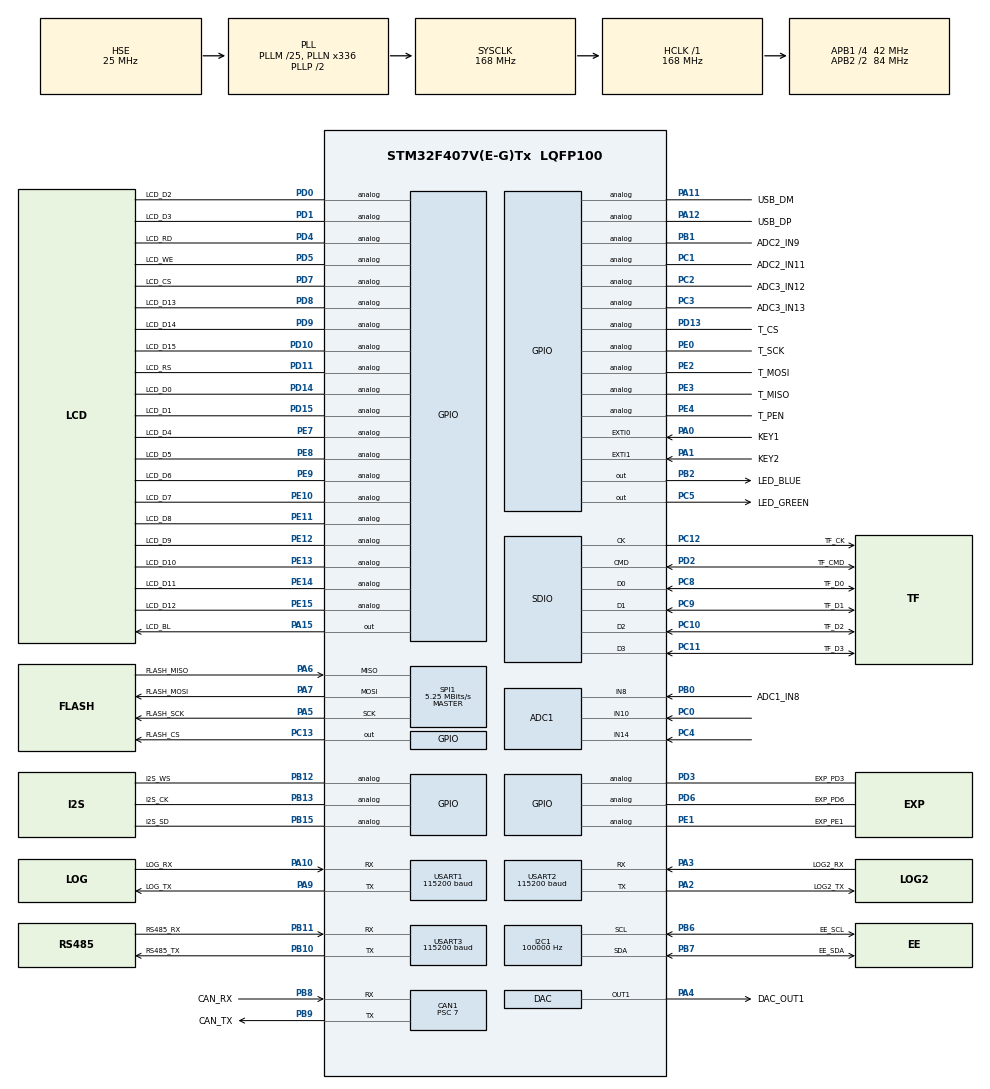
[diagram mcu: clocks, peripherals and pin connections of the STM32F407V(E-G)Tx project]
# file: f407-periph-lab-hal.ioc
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ADC1.Channel-0\#ChannelRegularConversion=ADC_CHANNEL_8
ADC1.Channel-1\#ChannelRegularConversion=ADC_CHANNEL_10
ADC1.Channel-2\#ChannelRegularConversion=ADC_CHANNEL_14
ADC1.Channel-3\#ChannelRegularConversion=ADC_CHANNEL_VREFINT
ADC1.NbrOfConversion=4
ADC1.NbrOfConversionFlag=1
ADC1.Rank-0\#ChannelRegularConversion=1
ADC1.Rank-1\#ChannelRegularConversion=2
ADC1.Rank-2\#ChannelRegularConversion=3
ADC1.Rank-3\#ChannelRegularConversion=4
ADC1.SamplingTime-0\#ChannelRegularConversion=ADC_SAMPLETIME_3CYCLES
ADC1.SamplingTime-1\#ChannelRegularConversion=ADC_SAMPLETIME_3CYCLES
ADC1.SamplingTime-2\#ChannelRegularConversion=ADC_SAMPLETIME_3CYCLES
ADC1.SamplingTime-3\#ChannelRegularConversion=ADC_SAMPLETIME_480CYCLES
ADC1.master=1
CAN1.BS1=CAN_BS1_8TQ
CAN1.BS2=CAN_BS2_3TQ
CAN1.CalculateBaudRate=499999
CAN1.CalculateTimeBit=2000
CAN1.CalculateTimeQuantum=166.66666666666669
CAN1.Prescaler=7
Dma.Request0=USART1_TX
Dma.USART1_TX.0.Direction=DMA_MEMORY_TO_PERIPH
Dma.USART1_TX.0.FIFOMode=DMA_FIFOMODE_DISABLE
Dma.USART1_TX.0.Instance=DMA2_Stream7
Dma.USART1_TX.0.MemDataAlignment=DMA_MDATAALIGN_BYTE
Dma.USART1_TX.0.MemInc=DMA_MINC_ENABLE
Dma.USART1_TX.0.Mode=DMA_NORMAL
Dma.USART1_TX.0.PeriphDataAlignment=DMA_PDATAALIGN_BYTE
Dma.USART1_TX.0.PeriphInc=DMA_PINC_DISABLE
Dma.USART1_TX.0.Priority=DMA_PRIORITY_LOW
I2C1.AddressingMode=I2C_ADDRESSINGMODE_7BIT
I2C1.ClockSpeed=100000
I2C1.OwnAddress1=0
IWDG.Prescaler=IWDG_PRESCALER_64
IWDG.Reload=4095
Mcu.Family=STM32F4
Mcu.Name=STM32F407V(E-G)Tx
Mcu.Package=LQFP100
NVIC.DMA2_Stream7_IRQn=true\:5\:0\:false\:false\:true\:false\:false\:false
NVIC.EXTI0_IRQn=true\:5\:0\:false\:false\:true\:false\:false\:false
NVIC.EXTI1_IRQn=true\:5\:0\:false\:false\:true\:false\:false\:false
NVIC.PriorityGroup=NVIC_PRIORITYGROUP_4
PA0-WKUP.GPIO_Label=KEY1
PA0-WKUP.GPIO_ModeDefaultEXTI=GPIO_MODE_IT_RISING
PA0-WKUP.GPIO_PuPd=GPIO_PULLDOWN
PA0-WKUP.Signal=GPXTI0
PA1.GPIO_Label=KEY2
PA1.GPIO_ModeDefaultEXTI=GPIO_MODE_IT_FALLING
PA1.GPIO_PuPd=GPIO_PULLUP
PA1.Signal=GPXTI1
PA10.GPIO_Label=LOG_RX
PA10.Mode=Asynchronous
PA10.Signal=USART1_RX
PA11.GPIO_Label=USB_DM
PA11.Signal=GPIO_Analog
PA12.GPIO_Label=USB_DP
PA12.Signal=GPIO_Analog
PA13.Mode=Serial_Wire
PA13.Signal=SYS_JTMS-SWDIO
PA14.Mode=Serial_Wire
PA14.Signal=SYS_JTCK-SWCLK
PA15.GPIO_Label=LCD_BL
PA15.GPIO_Speed=GPIO_SPEED_FREQ_LOW
PA15.PinState=GPIO_PIN_RESET
PA15.Signal=GPIO_Output
PA2.GPIO_Label=LOG2_TX
PA2.Mode=Asynchronous
PA2.Signal=USART2_TX
PA3.GPIO_Label=LOG2_RX
PA3.Mode=Asynchronous
PA3.Signal=USART2_RX
PA4.GPIO_Label=DAC_OUT1
PA4.GPIO_Mode=GPIO_MODE_ANALOG
PA4.GPIO_PuPd=GPIO_NOPULL
PA4.Signal=COMP_DAC1_group
PA5.GPIO_Label=FLASH_SCK
PA5.Mode=Full_Duplex_Master
PA5.Signal=SPI1_SCK
PA6.GPIO_Label=FLASH_MISO
PA6.Mode=Full_Duplex_Master
PA6.Signal=SPI1_MISO
PA7.GPIO_Label=FLASH_MOSI
PA7.Mode=Full_Duplex_Master
PA7.Signal=SPI1_MOSI
PA8.Signal=S_TIM1_CH1
PA9.GPIO_Label=LOG_TX
PA9.Mode=Asynchronous
PA9.Signal=USART1_TX
PB0.GPIO_Label=ADC1_IN8
PB0.Signal=ADCx_IN8
PB1.GPIO_Label=ADC2_IN9
PB1.Signal=GPIO_Analog
PB10.GPIO_Label=RS485_TX
PB10.Mode=Asynchronous
PB10.Signal=USART3_TX
PB11.GPIO_Label=RS485_RX
PB11.Mode=Asynchronous
PB11.Signal=USART3_RX
PB12.GPIO_Label=I2S_WS
PB12.Signal=GPIO_Analog
PB13.GPIO_Label=I2S_CK
PB13.Signal=GPIO_Analog
PB14.Signal=TIM8_CH2N
PB15.GPIO_Label=I2S_SD
PB15.Signal=GPIO_Analog
PB2.GPIO_Label=LED_BLUE
PB2.GPIO_Speed=GPIO_SPEED_FREQ_LOW
PB2.PinState=GPIO_PIN_SET
PB2.Signal=GPIO_Output
PB3.Signal=S_TIM2_CH2
PB4.GPIO_Label=ENC_A
PB4.Signal=S_TIM3_CH1
PB5.GPIO_Label=ENC_B
PB5.Signal=S_TIM3_CH2
PB6.GPIO_Label=EE_SCL
PB6.Mode=I2C
PB6.Signal=I2C1_SCL
PB7.GPIO_Label=EE_SDA
PB7.Mode=I2C
PB7.Signal=I2C1_SDA
PB8.GPIO_Label=CAN_RX
PB8.Mode=CAN_Activate
PB8.Signal=CAN1_RX
PB9.GPIO_Label=CAN_TX
PB9.Mode=CAN_Activate
PB9.Signal=CAN1_TX
PC0.Signal=ADCx_IN10
PC1.GPIO_Label=ADC2_IN11
PC1.Signal=GPIO_Analog
PC10.GPIO_Label=TF_D2
PC10.Mode=SD_4_bits_Wide_bus
PC10.Signal=SDIO_D2
PC11.GPIO_Label=TF_D3
PC11.Mode=SD_4_bits_Wide_bus
PC11.Signal=SDIO_D3
PC12.GPIO_Label=TF_CK
PC12.Mode=SD_4_bits_Wide_bus
PC12.Signal=SDIO_CK
PC13-ANTI_TAMP.GPIO_Label=FLASH_CS
PC13-ANTI_TAMP.GPIO_Speed=GPIO_SPEED_FREQ_LOW
PC13-ANTI_TAMP.PinState=GPIO_PIN_SET
PC13-ANTI_TAMP.Signal=GPIO_Output
PC14-OSC32_IN.Signal=RCC_OSC32_IN
PC15-OSC32_OUT.Signal=RCC_OSC32_OUT
PC2.GPIO_Label=ADC3_IN12
PC2.Signal=GPIO_Analog
PC3.GPIO_Label=ADC3_IN13
PC3.Signal=GPIO_Analog
PC4.Signal=ADCx_IN14
PC5.GPIO_Label=LED_GREEN
PC5.GPIO_Speed=GPIO_SPEED_FREQ_LOW
PC5.PinState=GPIO_PIN_RESET
PC5.Signal=GPIO_Output
PC6.Signal=S_TIM8_CH1
PC7.Signal=S_TIM8_CH2
PC8.GPIO_Label=TF_D0
PC8.Mode=SD_4_bits_Wide_bus
PC8.Signal=SDIO_D0
PC9.GPIO_Label=TF_D1
PC9.Mode=SD_4_bits_Wide_bus
PC9.Signal=SDIO_D1
PD0.GPIO_Label=LCD_D2
PD0.Signal=GPIO_Analog
PD1.GPIO_Label=LCD_D3
PD1.Signal=GPIO_Analog
PD10.GPIO_Label=LCD_D15
PD10.Signal=GPIO_Analog
PD11.GPIO_Label=LCD_RS
PD11.Signal=GPIO_Analog
PD12.Signal=S_TIM4_CH1
PD13.GPIO_Label=T_CS
PD13.Signal=GPIO_Analog
PD14.GPIO_Label=LCD_D0
PD14.Signal=GPIO_Analog
PD15.GPIO_Label=LCD_D1
PD15.Signal=GPIO_Analog
PD2.GPIO_Label=TF_CMD
PD2.Mode=SD_4_bits_Wide_bus
PD2.Signal=SDIO_CMD
PD3.GPIO_Label=EXP_PD3
PD3.Signal=GPIO_Analog
PD4.GPIO_Label=LCD_RD
PD4.Signal=GPIO_Analog
PD5.GPIO_Label=LCD_WE
PD5.Signal=GPIO_Analog
PD6.GPIO_Label=EXP_PD6
PD6.Signal=GPIO_Analog
PD7.GPIO_Label=LCD_CS
PD7.Signal=GPIO_Analog
PD8.GPIO_Label=LCD_D13
PD8.Signal=GPIO_Analog
PD9.GPIO_Label=LCD_D14
PD9.Signal=GPIO_Analog
PE0.GPIO_Label=T_SCK
PE0.Signal=GPIO_Analog
PE1.GPIO_Label=EXP_PE1
PE1.Signal=GPIO_Analog
PE10.GPIO_Label=LCD_D7
PE10.Signal=GPIO_Analog
PE11.GPIO_Label=LCD_D8
PE11.Signal=GPIO_Analog
PE12.GPIO_Label=LCD_D9
PE12.Signal=GPIO_Analog
PE13.GPIO_Label=LCD_D10
PE13.Signal=GPIO_Analog
PE14.GPIO_Label=LCD_D11
PE14.Signal=GPIO_Analog
PE15.GPIO_Label=LCD_D12
PE15.Signal=GPIO_Analog
PE2.GPIO_Label=T_MOSI
PE2.Signal=GPIO_Analog
PE3.GPIO_Label=T_MISO
PE3.Signal=GPIO_Analog
PE4.GPIO_Label=T_PEN
PE4.Signal=GPIO_Analog
PE5.Signal=S_TIM9_CH1
PE6.Signal=S_TIM9_CH2
PE7.GPIO_Label=LCD_D4
PE7.Signal=GPIO_Analog
PE8.GPIO_Label=LCD_D5
PE8.Signal=GPIO_Analog
PE9.GPIO_Label=LCD_D6
PE9.Signal=GPIO_Analog
PH0-OSC_IN.Mode=HSE-External-Oscillator
PH0-OSC_IN.Signal=RCC_OSC_IN
PH1-OSC_OUT.Mode=HSE-External-Oscillator
PH1-OSC_OUT.Signal=RCC_OSC_OUT
ProjectManager.HeapSize=0x200
ProjectManager.StackSize=0x1000
ProjectManager.TargetToolchain=MDK-ARM V5.27
RCC.48MHZClocksFreq_Value=48000000
RCC.AHBFreq_Value=168000000
RCC.APB1CLKDivider=RCC_HCLK_DIV4
RCC.APB1Freq_Value=42000000
RCC.APB1TimFreq_Value=84000000
RCC.APB2CLKDivider=RCC_HCLK_DIV2
RCC.APB2Freq_Value=84000000
RCC.APB2TimFreq_Value=168000000
RCC.CortexFreq_Value=168000000
RCC.HCLKFreq_Value=168000000
RCC.HSE_VALUE=25000000
RCC.HSI_VALUE=16000000
RCC.LSE_VALUE=32768
RCC.PLLM=25
RCC.PLLN=336
RCC.PLLQ=7
RCC.PLLSourceVirtual=RCC_PLLSOURCE_HSE
RCC.RTCClockSelection=RTC_CLKSOURCE_LSE
RCC.SYSCLKFreq_VALUE=168000000
RCC.SYSCLKSource=RCC_SYSCLKSOURCE_PLLCLK
RCC.VCOOutputFreq_Value=336000000
RTC.AsynchPrediv=127
RTC.HourFormat=RTC_HOURFORMAT_24
RTC.SynchPrediv=255
SH.ADCx_IN10.0=ADC1_IN10,IN10
SH.ADCx_IN14.0=ADC1_IN14,IN14
SH.ADCx_IN8.0=ADC1_IN8,IN8
SH.COMP_DAC1_group.0=DAC_OUT1,DAC_OUT1
SH.S_TIM1_CH1.0=TIM1_CH1
SH.S_TIM2_CH2.0=TIM2_CH2
SH.S_TIM3_CH1.0=TIM3_CH1
SH.S_TIM3_CH2.0=TIM3_CH2
SH.S_TIM4_CH1.0=TIM4_CH1
SH.S_TIM8_CH1.0=TIM8_CH1
SH.S_TIM8_CH2.0=TIM8_CH2
SH.S_TIM9_CH1.0=TIM9_CH1
SH.S_TIM9_CH2.0=TIM9_CH2
SPI1.BaudRatePrescaler=SPI_BAUDRATEPRESCALER_16
SPI1.CLKPhase=SPI_PHASE_1EDGE
SPI1.CLKPolarity=SPI_POLARITY_LOW
SPI1.CalculateBaudRate=5.25 MBits/s
SPI1.DataSize=SPI_DATASIZE_8BIT
SPI1.Direction=SPI_DIRECTION_2LINES
SPI1.FirstBit=SPI_FIRSTBIT_MSB
SPI1.Mode=SPI_MODE_MASTER
SPI1.NSS=SPI_NSS_SOFT
SPI1.VirtualType=VM_MASTER
TIM1.Channel-PWM\ Generation1\ CH1=TIM_CHANNEL_1
TIM1.Prescaler=0
TIM2.Channel-Input\ Capture2\ from\ TI2=TIM_CHANNEL_2
TIM2.Prescaler=0
TIM3.AutoReloadPreload=TIM_AUTORELOAD_PRELOAD_ENABLE
TIM3.EncoderMode=TIM_ENCODERMODE_TI12
TIM3.Period=65535
TIM4.Channel-PWM\ Generation1\ CH1=TIM_CHANNEL_1
TIM4.Prescaler=0
TIM5.Prescaler=0
TIM8.Channel-PWM\ Generation1\ CH1=TIM_CHANNEL_1
TIM8.Channel-PWM\ Generation2\ CH2=TIM_CHANNEL_2
TIM8.Channel-PWM\ Generation2\ CH2N=TIM_CCxN_ENABLE
TIM8.Prescaler=0
TIM9.Prescaler=0
USART1.BaudRate=115200
USART1.VirtualMode=VM_ASYNC
USART2.BaudRate=115200
USART2.VirtualMode=VM_ASYNC
USART3.BaudRate=115200
USART3.VirtualMode=VM_ASYNC
VP_ADC1_Vref_Input.Mode=IN-Vrefint
VP_CRC_VS_CRC.Mode=CRC_Activate
VP_IWDG_VS_IWDG.Mode=IWDG_Activate
VP_RNG_VS_RNG.Mode=RNG_Activate
VP_RTC_VS_RTC_Activate.Mode=RTC_Enabled
VP_RTC_VS_RTC_Calendar.Mode=RTC_Calendar
VP_TIM1_VS_ClockSourceINT.Mode=Internal
VP_TIM2_VS_ClockSourceINT.Mode=Internal
VP_TIM3_VS_ClockSourceINT.Mode=Internal
VP_TIM4_VS_ClockSourceINT.Mode=Internal
VP_TIM5_VS_ClockSourceINT.Mode=Internal
VP_TIM8_VS_ClockSourceINT.Mode=Internal
VP_TIM9_VS_ClockSourceINT.Mode=Internal
VP_WWDG_VS_WWDG.Mode=WWDG_Activate
WWDG.Counter=127
WWDG.Prescaler=WWDG_PRESCALER_8
WWDG.WindowValue=0x7F
board=custom

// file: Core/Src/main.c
/* USER CODE BEGIN Header */
/**
  ******************************************************************************
  * @file           : main.c
  * @brief          : Main program body
  ******************************************************************************
  * @attention
  *
  * Copyright (c) 2026 STMicroelectronics.
  * All rights reserved.
  *
  * This software is licensed under terms that can be found in the LICENSE file
  * in the root directory of this software component.
  * If no LICENSE file comes with this software, it is provided AS-IS.
  *
  ******************************************************************************
  */
/* USER CODE END Header */
#include "main.h"
#include "adc.h"
#include "can.h"
#include "crc.h"
#include "dac.h"
#include "dma.h"
#include "i2c.h"
#include "iwdg.h"
#include "rng.h"
#include "rtc.h"
#include "sdio.h"
#include "spi.h"
#include "tim.h"
#include "usart.h"
#include "wwdg.h"
#include "gpio.h"

/* USER CODE BEGIN Includes */
#include "app_main.h"

/* USER CODE END Includes */

void SystemClock_Config(void);

int main(void)
{

  /* MCU Configuration--------------------------------------------------------*/

  /* Reset of all peripherals, Initializes the Flash interface and the Systick. */
  HAL_Init();

  /* Configure the system clock */
  SystemClock_Config();

  /* Initialize all configured peripherals */
  MX_GPIO_Init();
  MX_DMA_Init();
  MX_USART1_UART_Init();
  MX_TIM3_Init();
  MX_TIM1_Init();
  MX_TIM2_Init();
  MX_TIM4_Init();
  MX_TIM5_Init();
  MX_TIM8_Init();
  MX_TIM9_Init();
  MX_USART2_UART_Init();
  MX_USART3_UART_Init();
  MX_CAN1_Init();
  MX_I2C1_Init();
  MX_SDIO_SD_Init();
  MX_SPI1_Init();
  MX_CRC_Init();
  MX_IWDG_Init();
  MX_RNG_Init();
  MX_RTC_Init();
  MX_WWDG_Init();
  MX_ADC1_Init();
  MX_DAC_Init();
  /* USER CODE BEGIN 2 */
  app_main();   /* never returns: teaching lab shell */
  /* USER CODE END 2 */

  /* Infinite loop */
  while (1)
  {

  }
}

void SystemClock_Config(void)
{
  RCC_OscInitTypeDef RCC_OscInitStruct = {0};
  RCC_ClkInitTypeDef RCC_ClkInitStruct = {0};

  /** Configure the main internal regulator output voltage
  */
  __HAL_RCC_PWR_CLK_ENABLE();
  __HAL_PWR_VOLTAGESCALING_CONFIG(PWR_REGULATOR_VOLTAGE_SCALE1);

  /** Initializes the RCC Oscillators according to the specified parameters
  * in the RCC_OscInitTypeDef structure.
  */
  RCC_OscInitStruct.OscillatorType = RCC_OSCILLATORTYPE_LSI|RCC_OSCILLATORTYPE_HSE;
  RCC_OscInitStruct.HSEState = RCC_HSE_ON;
  RCC_OscInitStruct.LSIState = RCC_LSI_ON;
  RCC_OscInitStruct.PLL.PLLState = RCC_PLL_ON;
  RCC_OscInitStruct.PLL.PLLSource = RCC_PLLSOURCE_HSE;
  RCC_OscInitStruct.PLL.PLLM = 25;
  RCC_OscInitStruct.PLL.PLLN = 336;
  RCC_OscInitStruct.PLL.PLLP = RCC_PLLP_DIV2;
  RCC_OscInitStruct.PLL.PLLQ = 7;
  if (HAL_RCC_OscConfig(&RCC_OscInitStruct) != HAL_OK)
  {
    Error_Handler();
  }

  /** Initializes the CPU, AHB and APB buses clocks
  */
  RCC_ClkInitStruct.ClockType = RCC_CLOCKTYPE_HCLK|RCC_CLOCKTYPE_SYSCLK
                              |RCC_CLOCKTYPE_PCLK1|RCC_CLOCKTYPE_PCLK2;
  RCC_ClkInitStruct.SYSCLKSource = RCC_SYSCLKSOURCE_PLLCLK;
  RCC_ClkInitStruct.AHBCLKDivider = RCC_SYSCLK_DIV1;
  RCC_ClkInitStruct.APB1CLKDivider = RCC_HCLK_DIV4;
  RCC_ClkInitStruct.APB2CLKDivider = RCC_HCLK_DIV2;

  if (HAL_RCC_ClockConfig(&RCC_ClkInitStruct, FLASH_LATENCY_5) != HAL_OK)
  {
    Error_Handler();
  }
}

void Error_Handler(void)
{
  __disable_irq();
  while (1)
  {
  }
}
